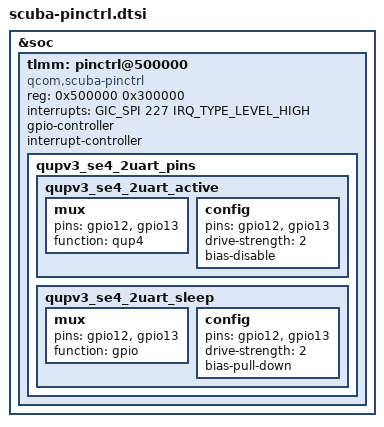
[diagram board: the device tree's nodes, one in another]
&soc {
	tlmm: pinctrl@500000 {
		compatible = "qcom,scuba-pinctrl";
		reg = <0x500000 0x300000>;
		interrupts = <GIC_SPI 227 IRQ_TYPE_LEVEL_HIGH>;
		gpio-controller;
		#gpio-cells = <2>;
		interrupt-controller;
		#interrupt-cells = <2>;

		qupv3_se4_2uart_pins: qupv3_se4_2uart_pins {
			qupv3_se4_2uart_active: qupv3_se4_2uart_active {
				mux {
					pins = "gpio12", "gpio13";
					function = "qup4";
				};

				config {
					pins = "gpio12", "gpio13";
					drive-strength = <2>;
					bias-disable;
				};
			};

			qupv3_se4_2uart_sleep: qupv3_se4_2uart_sleep {
				mux {
					pins = "gpio12", "gpio13";
					function = "gpio";
				};

				config {
					pins = "gpio12", "gpio13";
					drive-strength = <2>;
					bias-pull-down;
				};
			};
		};
	};
};
